AUTOSAR XML (schema 4-0-3)
standard types defined: Boolean, UInt16, UInt32, UInt8
package /AUTOSAR_Platform/DataConstrs
  range DC_Boolean: raw 0..1
  range DC_UInt16: raw 0..65535
  range DC_UInt8: raw 0..255
package /PATAC/MSM/ComponentTypes
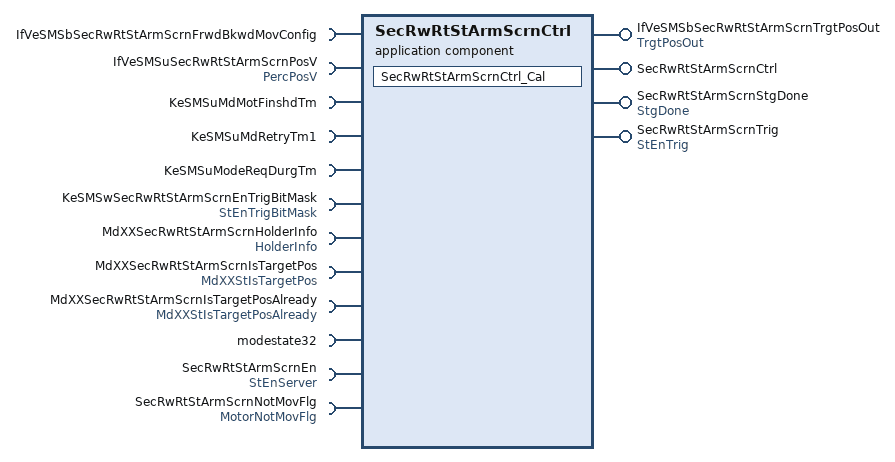
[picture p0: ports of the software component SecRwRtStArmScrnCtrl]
  application sw component type SecRwRtStArmScrnCtrl
    4 x provide port:
      IfVeSMSbSecRwRtStArmScrnTrgtPosOut: nonqueued-sender-com-spec{data-element=TrgtPosOut/Val, init-value=0}, provided-interface=TrgtPosOut
      SecRwRtStArmScrnCtrl: server-com-spec{operation=Cal, queue-length=1}, provided-interface=SecRwRtStArmScrnCtrl
      SecRwRtStArmScrnStgDone: nonqueued-sender-com-spec{data-element=StgDone/Val, init-value=0}, provided-interface=StgDone
      SecRwRtStArmScrnTrig: nonqueued-sender-com-spec{data-element=StEnTrig/Val, init-value=0}, provided-interface=StEnTrig
    12 x require port:
      IfVeSMSbSecRwRtStArmScrnFrwdBkwdMovConfig: nonqueued-receiver-com-spec{data-element=IfVeSMSbSecRwRtStArmScrnFrwdBkwdMovConfig/Val, filter=data-filter-type=ALWAYS, init-value=0}, required-interface=IfVeSMSbSecRwRtStArmScrnFrwdBkwdMovConfig
      IfVeSMSuSecRwRtStArmScrnPosV: nonqueued-receiver-com-spec{data-element=PercPosV/Val, filter=data-filter-type=ALWAYS, init-value=0}, required-interface=PercPosV
      KeSMSuMdMotFinshdTm: parameter-require-com-spec{init-value=0, parameter=KeSMSuMdMotFinshdTm/Val}, required-interface=KeSMSuMdMotFinshdTm
      KeSMSuMdRetryTm1: parameter-require-com-spec{init-value=0, parameter=KeSMSuMdRetryTm1/Val}, required-interface=KeSMSuMdRetryTm1
      KeSMSuModeReqDurgTm: parameter-require-com-spec{init-value=0, parameter=KeSMSuModeReqDurgTm/Val}, required-interface=KeSMSuModeReqDurgTm
      KeSMSwSecRwRtStArmScrnEnTrigBitMask: parameter-require-com-spec{init-value=6153, parameter=StEnTrigBitMask/Val}, required-interface=StEnTrigBitMask
      MdXXSecRwRtStArmScrnHolderInfo: nonqueued-receiver-com-spec{data-element=HolderInfo/Val, filter=data-filter-type=ALWAYS, init-value=0}, required-interface=HolderInfo
      MdXXSecRwRtStArmScrnIsTargetPos: nonqueued-receiver-com-spec{data-element=MdXXStIsTargetPos/Val, filter=data-filter-type=ALWAYS, init-value=0}, required-interface=MdXXStIsTargetPos
      MdXXSecRwRtStArmScrnIsTargetPosAlready: nonqueued-receiver-com-spec{data-element=MdXXStIsTargetPosAlready/Val, filter=data-filter-type=ALWAYS, init-value=0}, required-interface=MdXXStIsTargetPosAlready
      modestate32: nonqueued-receiver-com-spec{data-element=modestate32/Val, filter=data-filter-type=ALWAYS, init-value=0}, required-interface=modestate32
      SecRwRtStArmScrnEn: required-com-specs=[Clear, Get, Set], required-interface=StEnServer
      SecRwRtStArmScrnNotMovFlg: nonqueued-receiver-com-spec{data-element=MotorNotMovFlg/Val, filter=data-filter-type=ALWAYS, init-value=0}, required-interface=MotorNotMovFlg
    behavior SecRwRtStArmScrnCtrl_InternalBehavior
      operation invoked event OIT_SecRwRtStArmScrnCtrl_Cal_SecRwRtStArmScrnCtrl_Cal: start-on-event=SecRwRtStArmScrnCtrl_Cal, operation=SecRwRtStArmScrnCtrl.Cal
      runnable SecRwRtStArmScrnCtrl_Cal
        data-receive-point-by-arguments:
          7 x access:
            REC_IfVeSMSbSecRwRtStArmScrnFrwdBkwdMovConfig_Val: accessed-variable=IfVeSMSbSecRwRtStArmScrnFrwdBkwdMovConfig.Val
            REC_IfVeSMSuSecRwRtStArmScrnPosV_Val: accessed-variable=IfVeSMSuSecRwRtStArmScrnPosV.Val
            REC_MdXXSecRwRtStArmScrnHolderInfo_Val: accessed-variable=MdXXSecRwRtStArmScrnHolderInfo.Val
            REC_MdXXSecRwRtStArmScrnIsTargetPos_Val: accessed-variable=MdXXSecRwRtStArmScrnIsTargetPos.Val
            REC_MdXXSecRwRtStArmScrnIsTargetPosAlready_Val: accessed-variable=MdXXSecRwRtStArmScrnIsTargetPosAlready.Val
            REC_modestate32_Val: accessed-variable=modestate32.Val
            REC_SecRwRtStArmScrnNotMovFlg_Val: accessed-variable=SecRwRtStArmScrnNotMovFlg.Val
        data-send-points:
          access SEND_IfVeSMSbSecRwRtStArmScrnTrgtPosOut_Val: accessed-variable=IfVeSMSbSecRwRtStArmScrnTrgtPosOut.Val
          access SEND_SecRwRtStArmScrnStgDone_Val: accessed-variable=SecRwRtStArmScrnStgDone.Val
          access SEND_SecRwRtStArmScrnTrig_Val: accessed-variable=SecRwRtStArmScrnTrig.Val
        4 x parameter access:
          PA_KeSMSuMdMotFinshdTm_Val: accessed-parameter=KeSMSuMdMotFinshdTm.Val
          PA_KeSMSuMdRetryTm1_Val: accessed-parameter=KeSMSuMdRetryTm1.Val
          PA_KeSMSuModeReqDurgTm_Val: accessed-parameter=KeSMSuModeReqDurgTm.Val
          PA_KeSMSwSecRwRtStArmScrnEnTrigBitMask_Val: accessed-parameter=KeSMSwSecRwRtStArmScrnEnTrigBitMask.Val
        sync call SC_SecRwRtStArmScrnEn_Get: operation=SecRwRtStArmScrnEn.Get, timeout=0
  swc implementation SecRwRtStArmScrnCtrl_Implementation: behavior=SecRwRtStArmScrnCtrl_InternalBehavior
    code-descriptors:
      code Default: artifact-descriptors=autosar-engineering-object={short-label=Default, category=SWSRC}
package /PATAC/MSM/ModeAdjust/CalPortInterface
  parameter interface KeSMSuMdMotFinshdTm
    parameter data prototype Val: sw-calibration-access=READ-WRITE, type=UInt16
  parameter interface KeSMSuModeReqDurgTm
    parameter data prototype Val: sw-calibration-access=READ-WRITE, type=UInt16
  parameter interface StEnTrigBitMask
    parameter data prototype Val: sw-calibration-access=READ-WRITE, type=UInt32
package /PATAC/MSM/ModeAdjust/PortInterface
  client server interface SecRwRtStArmScrnCtrl
    operation Cal
  client server interface StEnServer
    operation Clear
      arg data: type=UInt8, direction=IN, server-argument-impl-policy=USE-ARGUMENT-TYPE
    operation Get
      arg data: type=UInt32, direction=OUT, server-argument-impl-policy=USE-ARGUMENT-TYPE
    operation Set
      arg data: type=UInt8, direction=IN, server-argument-impl-policy=USE-ARGUMENT-TYPE
  10 x sender receiver interface:
    HolderInfo: invalidation-policy{data-element=HolderInfo/Val, handle-invalid=DONT-INVALIDATE}
      data Val: type=UInt32
    IfVeSMSbSecRwRtStArmScrnFrwdBkwdMovConfig: invalidation-policy{data-element=IfVeSMSbSecRwRtStArmScrnFrwdBkwdMovConfig/Val, handle-invalid=DONT-INVALIDATE}
      data Val: type=Boolean
    MdXXStIsTargetPos: invalidation-policy{data-element=MdXXStIsTargetPos/Val, handle-invalid=DONT-INVALIDATE}
      data Val: type=UInt32
    MdXXStIsTargetPosAlready: invalidation-policy{data-element=MdXXStIsTargetPosAlready/Val, handle-invalid=DONT-INVALIDATE}
      data Val: type=UInt32
    modestate32: invalidation-policy{data-element=modestate32/Val, handle-invalid=DONT-INVALIDATE}
      data Val: type=UInt32
    MotorNotMovFlg: invalidation-policy{data-element=MotorNotMovFlg/Val, handle-invalid=DONT-INVALIDATE}
      data Val: type=Boolean
    PercPosV: invalidation-policy{data-element=PercPosV/Val, handle-invalid=DONT-INVALIDATE}
      data Val: type=Boolean
    StEnTrig: invalidation-policy{data-element=StEnTrig/Val, handle-invalid=DONT-INVALIDATE}
      data Val: type=Boolean
    StgDone: invalidation-policy{data-element=StgDone/Val, handle-invalid=DONT-INVALIDATE}
      data Val: type=Boolean
    TrgtPosOut: invalidation-policy{data-element=TrgtPosOut/Val, handle-invalid=DONT-INVALIDATE}
      data Val: type=Boolean
package /PATAC/MSM/PortInterfaces
  parameter interface KeSMSuMdRetryTm1
    parameter data prototype Val: sw-calibration-access=READ-WRITE, type=UInt8
